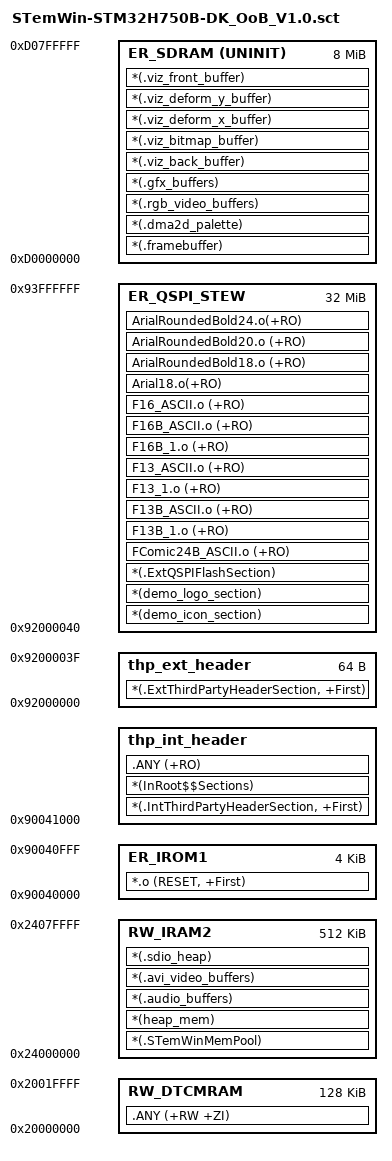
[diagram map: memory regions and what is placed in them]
; *************************************************************
; *** Scatter-Loading Description File generated by uVision ***
; *************************************************************

LR_IROM1 0x90040000  0x1000   {    ; load region size_region
	ER_IROM1 0x90040000 0x1000 {
		*.o (RESET, +First)
}
}

LR_IROM-ST 0x90041000   {    ; load region size_region
  thp_int_header  0x90041000   { 
		*(.IntThirdPartyHeaderSection, +First)
		*(InRoot$$Sections)
		 .ANY (+RO)  
	}

  RW_DTCMRAM 0x20000000 0x20000 {
  		.ANY (+RW +ZI)
    }
  RW_IRAM2 0x24000000 0x00080000  {
  		*(.STemWinMemPool)
		*(heap_mem)
		*(.audio_buffers)
        *(.avi_video_buffers)
		*(.sdio_heap)
  }
}

LR_QSPI_STEW  0x92000000  {
	thp_ext_header  0x92000000  0x40 { 
		*(.ExtThirdPartyHeaderSection, +First)   
	}
  ER_SDRAM 0xD0000000 UNINIT 0x800000{ 
  		*(.framebuffer)
		*(.dma2d_palette)
		*(.rgb_video_buffers)
		*(.gfx_buffers)
		*(.viz_back_buffer)
		*(.viz_bitmap_buffer)
		*(.viz_deform_x_buffer)
		*(.viz_deform_y_buffer)
		*(.viz_front_buffer)		
}

	
ER_QSPI_STEW  0x92000040 0x1FFFFC0 {

		*(demo_icon_section)
		*(demo_logo_section)
		*(.ExtQSPIFlashSection)
		FComic24B_ASCII.o (+RO)
		F13B_1.o (+RO)
		F13B_ASCII.o (+RO)
		F13_1.o (+RO)
		F13_ASCII.o (+RO)
		F16B_1.o (+RO)
		F16B_ASCII.o (+RO)
		F16_ASCII.o (+RO)
		Arial18.o(+RO)
		ArialRoundedBold18.o (+RO)
		ArialRoundedBold20.o (+RO)
		ArialRoundedBold24.o(+RO)

	}
}
